# XMC4700 register map
Vendor: Infineon; File version: 1.3.0 (Reference Manual v1.3)
CPU: CM4 r2p0, little endian, MPU, FPU, 6 interrupt priority bits
Registers are 32-bit, read-write, reset 0x0 unless marked. A register's access mark holds for its fields unless they carry their own. Offsets are from the block's base; [hi:lo] are bit positions.

## DSD_CH0 — Delta Sigma Demodulator
Base 0x40008100
Same registers: DSD_CH1 0x40008200, DSD_CH2 0x40008300, DSD_CH3 0x40008400
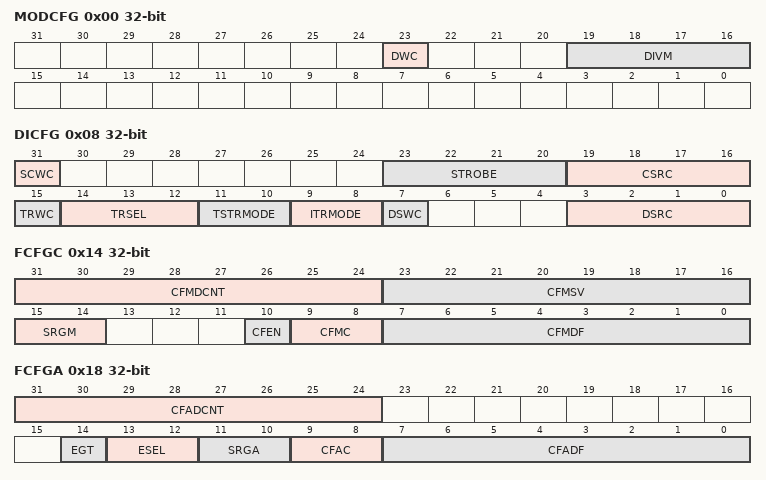
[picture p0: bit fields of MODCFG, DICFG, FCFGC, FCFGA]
0x00 MODCFG access per field — Modulator Configuration Register
  [23] DWC wo — Write Control for Divider Factor
    0=No write access to divider factor; 1=Bitfield DIVM can be written
  [19:16] DIVM rw — Divider Factor for Modulator Clock
    0=fMOD = fCLK / 2; 1=fMOD = fCLK / 4; 2=fMOD = fCLK / 6; 15=fMOD = fCLK / 32
0x08 DICFG access per field — Demodulator Input Configuration Register
  [31] SCWC wo — Write Control for Strobe/Clock Selection
    0=No write access to strobe/clock parameters; 1=Bitfields STROBE, CSRC can be written
  [23:20] STROBE rw — Data Strobe Generatoion Mode
    0=No data strobe; 1=Direct clock, a sample trigger is generated at each rising clock edge; 2=Direct clock, a sample trigger is generated at each falling clock edge; 3=Double data, a sample trigger is generated at each rising and falling clock edge; 5=Double clock, a sample trigger is generated at every 2nd rising clock edge; 6=Double clock, a sample trigger is generated at every 2nd falling clock edge
  [19:16] CSRC rw — Sample Clock Source Select
    1=External, from input A; 2=External, from input B; 3=External, from input C; 4=External, from input D; 15=Internal clock
  [15] TRWC wo — Write Control for Trigger Parameters
    0=No write access to trigger parameters; 1=Bitfields TRSEL, TSTRMODE, ITRMODE can be written
  [14:12] TRSEL rw — Trigger Select
  [11:10] TSTRMODE rw — Timestamp Trigger Mode
    0=No timestamp trigger; 1=Trigger event upon a falling edge; 2=Trigger event upon a rising edge; 3=Trigger event upon each edge
  [9:8] ITRMODE rw — Integrator Trigger Mode
    0=No integration trigger, integrator bypassed, INTEN = 0 all the time; 1=Trigger event upon a falling edge; 2=Trigger event upon a rising edge; 3=No trigger, integrator active all the time, INTEN = 1 all the time
  [7] DSWC wo — Write Control for Data Selection
    0=No write access to data parameters; 1=Bitfield DSRC can be written
  [3:0] DSRC rw — Input Data Source Select
    0b000X=Disconnected; 2=External, from input A, direct; 3=External, from input A, inverted; 4=External, from input B, direct; 5=External, from input B, inverted
0x14 FCFGC access per field — Filter Configuration Register, Main CIC Filter
  [31:24] CFMDCNT ro — CIC Filter (Main Chain) Decimation Counter
  [23:16] CFMSV rw — CIC Filter (Main Chain) Start Value
  [15:14] SRGM rw — Service Request Generation Main Chain
    0=Never, service requests disabled; 3=Always, for each new result value
  [10] CFEN rw — CIC Filter Enable
    0=CIC filter disabled and bypassed; 1=Enable CIC filter
  [9:8] CFMC rw — CIC Filter (Main Chain) Configuration
    0=CIC1; 1=CIC2; 2=CIC3; 3=CICF
  [7:0] CFMDF rw — CIC Filter (Main Chain) Decimation Factor
0x18 FCFGA access per field — Filter Configuration Register, Auxiliary Filter
  [31:24] CFADCNT ro — CIC Filter (Auxiliary) Decimation Counter
  [14] EGT rw — Event Gating
    0=Separate: generate events according to ESEL; 1=Coupled: generate events only when the integrator is enabled and after the discard phase defined by bitfield NVALDISWhile the integrator is bypassed, event gating is disabled, i.e. service requests are generated according to bitfield ESEL. The event gating suppresses service requests, result values are still stored in register RESAx.
  [13:12] ESEL rw — Event Select
    0=Always, for each new result value; 1=If result is inside the boundary band; 2=If result is outside the boundary band
  [11:10] SRGA rw — Service Request Generation Auxiliary Filter
    0=Never, service requests disabled; 1=Auxiliary filter: As selected by bitfields ESEL and EGT (if integrator enabled); 2=Alternate source: Capturing of a sign delay value to register CGSYNCx (x = 0 - 3)
  [9:8] CFAC rw — CIC Filter (Auxiliary) Configuration
    0=CIC1; 1=CIC2; 2=CIC3; 3=CICF
  [7:0] CFADF rw — CIC Filter (Auxiliary) Decimation Factor
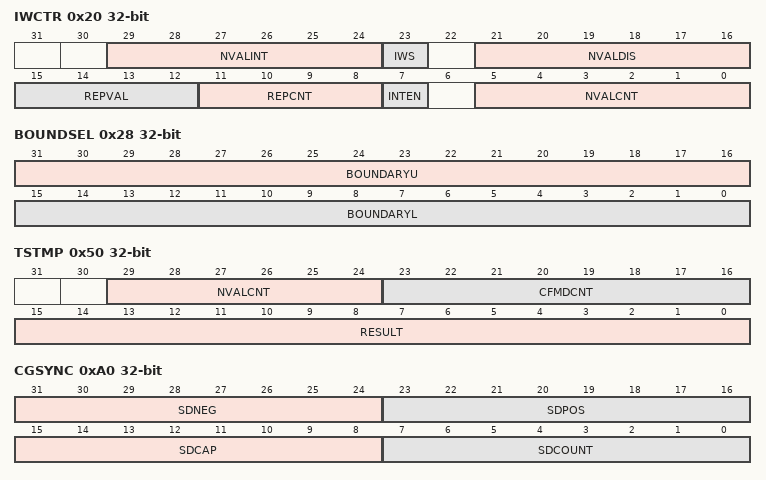
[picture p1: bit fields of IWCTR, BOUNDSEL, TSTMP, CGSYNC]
0x20 IWCTR access per field — Integration Window Control Register
  [29:24] NVALINT rw — Number of Values Integrated
  [23] IWS rw — Integration Window SIze
    0=Internal control: stop integrator after REPVAL+1 integration cycles; 1=External control: stop integrator when bit INTEN becomes 0
  [21:16] NVALDIS rw — Number of Values Discarded
  [15:12] REPVAL rw — Number of Integration Cycles
  [11:8] REPCNT ro — Integration Cycle Counter
  [7] INTEN ro — Integration Enable
    0=Integration stopped. INTEN is cleared at the end of the integration window, i.e. upon the inverse trigger event transition of the external trigger signal.; 1=Integration enabled. INTEN is set upon the defined trigger event.
  [5:0] NVALCNT ro — Number of Values Counted
0x28 BOUNDSEL — Boundary Select Register
  [31:16] BOUNDARYU — Upper Boundary Value for Limit Checking
  [15:0] BOUNDARYL — Lower Boundary Value for Limit Checking
0x30 RESM ro — Result Register, Main Filter
  [15:0] RESULT — Result of most recent conversion
0x38 OFFM — Offset Register, Main Filter
  [15:0] OFFSET — Offset Value
0x40 RESA ro — Result Register, Auxiliary Filter
  [15:0] RESULT — Result of most recent conversion
0x50 TSTMP ro — Time-Stamp Register
  [29:24] NVALCNT — Number of Values Counted
  [23:16] CFMDCNT — CIC Filter (Main Chain) Decimation Counter
  [15:0] RESULT — Result of most recent conversion
0xA0 CGSYNC access per field — Carrier Generator Synchronization Register
  [31:24] SDNEG rw — Sign Delay Value for Negative Halfwave
  [23:16] SDPOS rw — Sign Delay Value for Positive Halfwave
  [15:8] SDCAP ro — Sign Delay Capture Value
  [7:0] SDCOUNT ro — Sign Delay Counter
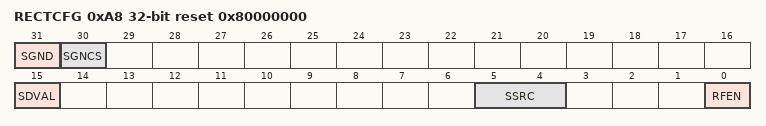
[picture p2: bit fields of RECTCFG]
0xA8 RECTCFG access per field reset 0x80000000 — Rectification Configuration Register
  [31] SGND ro — Sign Signal Delayed
    0=Positive values; 1=Negative values
  [30] SGNCS ro — Selected Carrier Sign Signal
    0=Positive values; 1=Negative values
  [15] SDVAL ro — Valid Flag
    0=No new result available; 1=Bitfield SDCAP has been updated with a new captured value and has not yet been read
  [5:4] SSRC rw — Sign Source
    0=On-chip carrier generator; 1=Sign of result of next channel; 2=External sign signal A; 3=External sign signal B
  [0] RFEN rw — Rectification Enable
    0=No rectification, data not altered; 1=Data are rectified according to SGND
